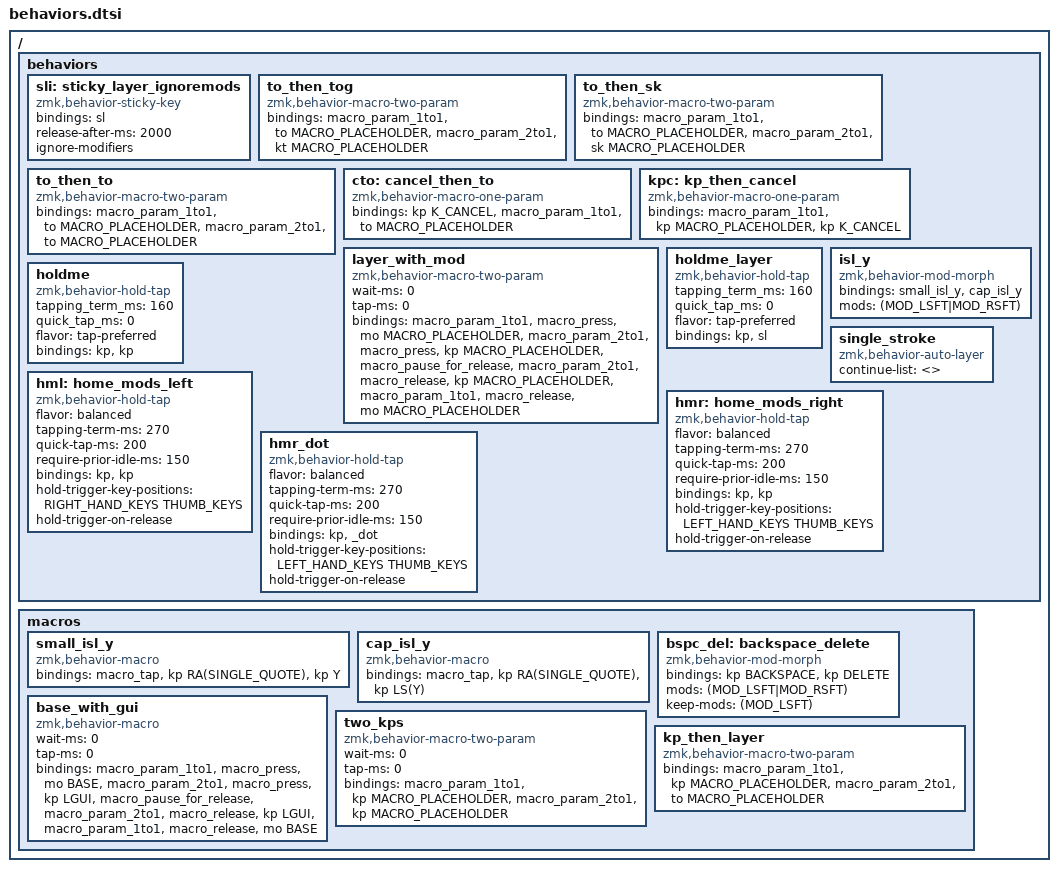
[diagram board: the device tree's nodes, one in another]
#include "navigation.dtsi"
#include "numword.dtsi"
#include "capsword.dtsi"
#include "mouse.dtsi"
#include "adaptive_keys.dtsi"
#include "mod_locks.dtsi"
#include "strict_kps.dtsi"
#include "convenience_mod_morphs.dtsi"
#include "scroller.dtsi"
/ {
	behaviors {
		
		// Gerði þetta því vildi sl numword -> halda gui til að skipta um workspaces
		// en virkar auðvitað ekki því vil ekki tölurnar á numword séu hold taps
		// en kannski vil ég þetta seinna í eitthvað annað
		sli: sticky_layer_ignoremods {
			compatible = "zmk,behavior-sticky-key";
			#binding-cells = <1>;
			bindings = <&sl>;
			release-after-ms = <2000>;
			ignore-modifiers;
		};
		
		to_then_tog: to_then_tog {
			compatible = "zmk,behavior-macro-two-param";
			#binding-cells = <2>;
			bindings =  <&macro_param_1to1>, <&to MACRO_PLACEHOLDER>,
			<&macro_param_2to1>, <&kt MACRO_PLACEHOLDER>;
		};
		
		to_then_sk: to_then_sk {
			compatible = "zmk,behavior-macro-two-param";
			#binding-cells = <2>;
			bindings =  <&macro_param_1to1>, <&to MACRO_PLACEHOLDER>,
			<&macro_param_2to1>, <&sk MACRO_PLACEHOLDER>;
		};
		
		to_then_to: to_then_to {
			compatible = "zmk,behavior-macro-two-param";
			#binding-cells = <2>;
			bindings =  <&macro_param_1to1>, <&to MACRO_PLACEHOLDER>,
			<&macro_param_2to1>, <&to MACRO_PLACEHOLDER>;
		};
		
		cto: cancel_then_to {
			compatible = "zmk,behavior-macro-one-param";
			#binding-cells = <1>;
			bindings = <&kp K_CANCEL>, <&macro_param_1to1>, <&to MACRO_PLACEHOLDER>;
		};
		
		kpc: kp_then_cancel {
			compatible = "zmk,behavior-macro-one-param";
			#binding-cells = <1>;
			bindings = <&macro_param_1to1>, <&kp MACRO_PLACEHOLDER>, <&kp K_CANCEL>;
		};
		
		layer_with_mod: layer_with_mod {
			compatible = "zmk,behavior-macro-two-param";
			wait-ms = <0>;
			tap-ms = <0>;
			#binding-cells = <2>;
			bindings
			= <&macro_param_1to1>
			, <&macro_press &mo MACRO_PLACEHOLDER>
			, <&macro_param_2to1>
			, <&macro_press &kp MACRO_PLACEHOLDER>
			, <&macro_pause_for_release>
			, <&macro_param_2to1>
			, <&macro_release &kp MACRO_PLACEHOLDER>
			, <&macro_param_1to1>
			, <&macro_release &mo MACRO_PLACEHOLDER>
			;
		};
		
		
		/* movegui_word: movegui_word { */
			/* 	compatible = "zmk,behavior-tri-state"; */
			/* 	#binding-cells = <0>; */
			/* 	bindings = <&to_then_tog NAVIGATION LGUI>, <&none>, <&to_then_tog BASE LGUI>; */
			/* 	ignored-key-positions = < */
			/* 	POS_LH_C5R2 POS_LH_C4R2 POS_LH_C3R2 POS_LH_C2R2 POS_LH_C1R2     POS_RH_C1R2 POS_RH_C2R2 POS_RH_C3R2 POS_RH_C4R2 POS_RH_C5R2 */
			/* 	POS_LH_C4R4 POS_LH_C3R4 POS_LH_C2R4                 POS_RH_C1R4 POS_RH_C2R4 POS_RH_C3R4 POS_RH_C4R4 */
			/* 	POS_LH_T1 */
			/* 	>; */
			/* 	ignored-layers = <NAVIGATION>; */
			/* 	timeout-ms = <4000>; */
		/* }; */


		holdme_layer: holdme_layer {
			compatible = "zmk,behavior-hold-tap";
			#binding-cells = <2>;
			tapping_term_ms = <160>;
			quick_tap_ms = <0>;
			flavor = "tap-preferred";
			bindings = <&kp>, <&sl>;
		};
	};
	
	macros {
		small_isl_y: small_isl_y {
			compatible = "zmk,behavior-macro";
			#binding-cells = <0>;
			bindings = <&macro_tap &kp RA(SINGLE_QUOTE) &kp Y>;
		};
		
		cap_isl_y: cap_isl_y {
			compatible = "zmk,behavior-macro";
			#binding-cells = <0>;
			bindings = <&macro_tap &kp RA(SINGLE_QUOTE) &kp LS(Y)>;
		};
		
		bspc_del: backspace_delete {
			compatible = "zmk,behavior-mod-morph";
			#binding-cells = <0>;
			bindings = <&kp BACKSPACE>, <&kp DELETE>;
			mods = <(MOD_LSFT|MOD_RSFT)>;
			keep-mods = <(MOD_LSFT)>;
		};
		
		base_with_gui: base_with_gui {
			compatible = "zmk,behavior-macro";
			#binding-cells = <0>;
			wait-ms = <0>;
			tap-ms = <0>;
			bindings
			= <&macro_param_1to1>
			, <&macro_press &mo BASE>
			, <&macro_param_2to1>
			, <&macro_press &kp LGUI>
			, <&macro_pause_for_release>
			, <&macro_param_2to1>
			, <&macro_release &kp LGUI>
			, <&macro_param_1to1>
			, <&macro_release &mo BASE>
			;
		};
		
		#define UNICODE(name, ...) \
		ZMK_MACRO(name, \
		wait-ms = <1>; \
		tap-ms = <1>; \
		bindings = __VA_ARGS__; \
		)
		
		UNICODE(degsign, /* ° */
		<&kp LC(LS(U))>,
		<&kp B &kp N0 &kp ENTER>
		)
		
		UNICODE(polish_l,
		<&kp LC(LS(U))>,
		<&kp N1 &kp N4 &kp N2 &kp ENTER>
		)
		UNICODE(polish_capital_l,
		<&kp LC(LS(U))>,
		<&kp N1 &kp N4 &kp N1 &kp ENTER>
		)
		
		
		two_kps: two_kps {
			compatible = "zmk,behavior-macro-two-param";
			#binding-cells = <2>;
			/* wait-ms = <40>; */
			/* tap-ms = <40>; */
			wait-ms = <0>;
			tap-ms = <0>;
			bindings =  <&macro_param_1to1>, <&kp MACRO_PLACEHOLDER>,
			<&macro_param_2to1>, <&kp MACRO_PLACEHOLDER>;
		};
		
		kp_then_layer: kp_then_layer {
			compatible = "zmk,behavior-macro-two-param";
			#binding-cells = <2>;
			bindings
			= <&macro_param_1to1>, <&kp MACRO_PLACEHOLDER>,
			<&macro_param_2to1>, <&to MACRO_PLACEHOLDER>;
		};
	};
	
	
	behaviors {
		isl_y: isl_y {
			compatible = "zmk,behavior-mod-morph";
			#binding-cells = <0>;
			bindings = <&small_isl_y>, <&cap_isl_y>;
			mods = <(MOD_LSFT|MOD_RSFT)>;
		};
		
		holdme: holdme {
			compatible = "zmk,behavior-hold-tap";
			#binding-cells = <2>;
			tapping_term_ms = <160>;
			quick_tap_ms = <0>;
			flavor = "tap-preferred";
			bindings = <&kp>, <&kp>;
		};
		
		single_stroke: single_stroke {
			compatible = "zmk,behavior-auto-layer";
			#binding-cells = <1>;
			continue-list = <>;
		};
		
		/* sk_sh_o: sticky_shift_with_overlay { */
			/* 	compatible = "zmk,behavior-macro"; */
			/* 	#binding-cells = <0>; */
			/* 	bindings = < */
			/* 	&sk LSHIFT */
			/* 	&single_stroke KCAN_OVER */
			/* 	>; */
		/* }; */
		
		/* sksh: sksh { */
			/* 	compatible = "zmk,behavior-hold-tap"; */
			/* 	#binding-cells = <2>; */
			/* 	flavor = "balanced"; */
			/* 	tapping-term-ms = <200>; */
			/* 	bindings = <&kp>, <&sk_sh_o>; */
		/* }; */
		
		// |------------------------|------------------------|
		// | LEFT_HAND_KEYS         |        RIGHT_HAND_KEYS |
		// |                        |                        |
		// |  0  1  2  3  4         |          5  6  7  8  9 |
		// | 10 11 12 13 14 15      |      16 17 18 19 20 21 |
		// | 22 23 24 25 26 27      |      28 29 30 31 32 33 |
		// | 34 35 36 37 38 39      |      40 41 42 43 44 45 |
		// | 46 47 48 49 50 51      |      58 59 60 61 62 63 |
		// | 64 65 66 67 68         |         75 76 77 78 79 |
		// |                69 52   |   57 74                |
		// |                 70 53  |  56 73                 |
		// |                  71 54 | 55 72                  |
		// |------------------------|------------------------|
		//
		#define LEFT_HAND_KEYS      \
		0  1  2  3  4       \
		10 11 12 13 14 15    \
		22 23 24 25 26 27    \
		34 35 36 37 38 39    \
		46 47 48 49 50 51    \
		64 65 66 67 68
		#define RIGHT_HAND_KEYS     \
		5  6  7  8  9 \
		16 17 18 19 20 21 \
		28 29 30 31 32 33 \
		40 41 42 43 44 45 \
		58 59 60 61 62 63 \
		75 76 77 78 79
		#define THUMB_KEYS          \
		69 52       57 74                \
		70 53     56 73                 \
		71 54   55 72
		
		
		
		hml: home_mods_left {
			compatible = "zmk,behavior-hold-tap";
			#binding-cells = <2>;
			flavor = "balanced";
			// út af require-prior-idle-ms og flavor = balanced
			// kemur tapping-term-ms ekki mikið við sögu, 
			// hér eru samt tvær aðstæður þar sem það verður relevant:
			// ef þú vilt gera mod+bokstaf á sömu hlið, 
			// td halda inni hrm fyrir LGUI og svo yta á bókstaf á sömu hlið,
			// getur þá bara haldið inni aðeins lengur
			// sama ef vilt halda inni LGUI og ýta á músartakka
			// (með actual mús)
			// annað: ef vilt actually ýta á mod sem takka, 
			// td ýta á """windows""" takkann til að fá upp menu
			// þarft þá að halda honum inni tapping-term-ms lengi
			tapping-term-ms = <270>;
			quick-tap-ms = <200>;
			require-prior-idle-ms = <150>;
			bindings = <&kp>, <&kp>;
			hold-trigger-key-positions = <RIGHT_HAND_KEYS THUMB_KEYS>;
			// hold-trigger-on-release lætur hold-trigger-key-positions
			// resolveast eftir release, ekki press, sem er nauðsynlegt
			// fyrir að combinea mods, td gui + ctrl eða whatever
			hold-trigger-on-release;
		};
		
		hmr: home_mods_right {
			compatible = "zmk,behavior-hold-tap";
			#binding-cells = <2>;
			flavor = "balanced";
			tapping-term-ms = <270>;
			quick-tap-ms = <200>;
			require-prior-idle-ms = <150>;
			bindings = <&kp>, <&kp>;
			hold-trigger-key-positions = <LEFT_HAND_KEYS THUMB_KEYS>;
			hold-trigger-on-release;
		};
		
		hmr_dot: hmr_dot {
			compatible = "zmk,behavior-hold-tap";
			#binding-cells = <2>;
			flavor = "balanced";
			tapping-term-ms = <270>;
			quick-tap-ms = <200>;
			require-prior-idle-ms = <150>;
			bindings = <&kp>, <&_dot>;
			hold-trigger-key-positions = <LEFT_HAND_KEYS THUMB_KEYS>;
			hold-trigger-on-release;
		};
	};
	
};
